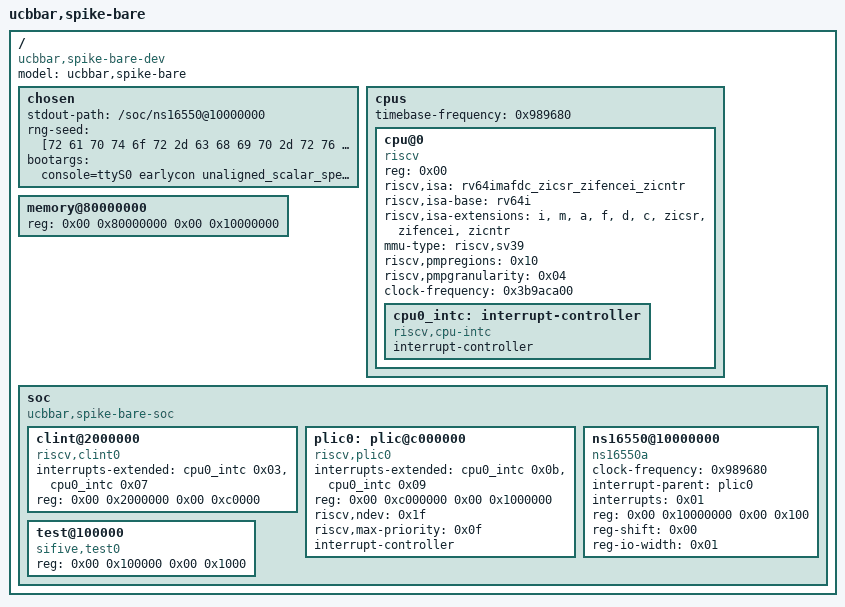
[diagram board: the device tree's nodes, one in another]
/dts-v1/;

/ {
	#address-cells = <0x02>;
	#size-cells = <0x02>;
	compatible = "ucbbar,spike-bare-dev";
	model = "ucbbar,spike-bare";

	chosen {
		stdout-path = "/soc/ns16550@10000000";
		/* Deterministic simulation seed: without a hardware RNG, waiting for
		 * the CRNG to collect timer entropy costs billions of RTL cycles. */
		rng-seed = [72 61 70 74 6f 72 2d 63 68 69 70 2d 72 76 36 34
		            2d 67 63 2d 73 69 6d 2d 62 6f 6f 74 2d 73 65
		            65 64 2d 30 31 2d 64 65 74 65 72 6d 69 6e 69
		            73 74 69 63 2d 6f 6e 6c 79 2d 30 30 30 31 21];
		/* The fast Buildroot kernel omits binfmt_script, while /init is a
		 * shell script. Run its devtmpfs setup through BusyBox sh, then enter
		 * the lp64d init ELF. Arguments after "--" are passed to rdinit. */
		/* NPC's scalar misaligned accesses have been measured as fast.  Tell
		 * Linux explicitly so cycle-accurate simulation does not spend tens of
		 * minutes repeating the boot-time speed benchmark. */
		bootargs = "console=ttyS0 earlycon unaligned_scalar_speed=fast cryptomgr.notests=1 initcall_blacklist=jent_mod_init random.trust_bootloader=on rdinit=/bin/sh -- -c \"mount -t devtmpfs devtmpfs /dev; exec /sbin/init\"";
	};

	cpus {
		#address-cells = <0x01>;
		#size-cells = <0x00>;
		timebase-frequency = <0x989680>;

		cpu@0 {
			device_type = "cpu";
			reg = <0x00>;
			status = "okay";
			compatible = "riscv";
			/* rv64gc = rv64imafd + C. F/D present so a hard-float
			 * (lp64d) Buildroot userspace boots correctly. */
			riscv,isa = "rv64imafdc_zicsr_zifencei_zicntr";
			riscv,isa-base = "rv64i";
			riscv,isa-extensions = "i", "m", "a", "f", "d", "c", "zicsr", "zifencei", "zicntr";
			mmu-type = "riscv,sv39";
			riscv,pmpregions = <0x10>;
			riscv,pmpgranularity = <0x04>;
			clock-frequency = <0x3b9aca00>;

			cpu0_intc: interrupt-controller {
				#address-cells = <0x02>;
				#interrupt-cells = <0x01>;
				interrupt-controller;
				compatible = "riscv,cpu-intc";
			};
		};
	};

	memory@80000000 {
		device_type = "memory";
		reg = <0x00 0x80000000 0x00 0x10000000>;
	};

	soc {
		#address-cells = <0x02>;
		#size-cells = <0x02>;
		compatible = "ucbbar,spike-bare-soc", "simple-bus";
		ranges;

		clint@2000000 {
			compatible = "riscv,clint0";
			interrupts-extended = <&cpu0_intc 0x03 &cpu0_intc 0x07>;
			reg = <0x00 0x2000000 0x00 0xc0000>;
		};

		plic0: plic@c000000 {
			compatible = "riscv,plic0";
			#address-cells = <0x02>;
			interrupts-extended = <&cpu0_intc 0x0b &cpu0_intc 0x09>;
			reg = <0x00 0xc000000 0x00 0x1000000>;
			riscv,ndev = <0x1f>;
			riscv,max-priority = <0x0f>;
			#interrupt-cells = <0x01>;
			interrupt-controller;
			phandle = <0x02>;
		};

		ns16550@10000000 {
			compatible = "ns16550a";
			clock-frequency = <0x989680>;
			interrupt-parent = <&plic0>;
			interrupts = <0x01>;
			reg = <0x00 0x10000000 0x00 0x100>;
			reg-shift = <0x00>;
			reg-io-width = <0x01>;
		};

		test@100000 {
			compatible = "sifive,test0";
			reg = <0x00 0x100000 0x00 0x1000>;
		};
	};
};
